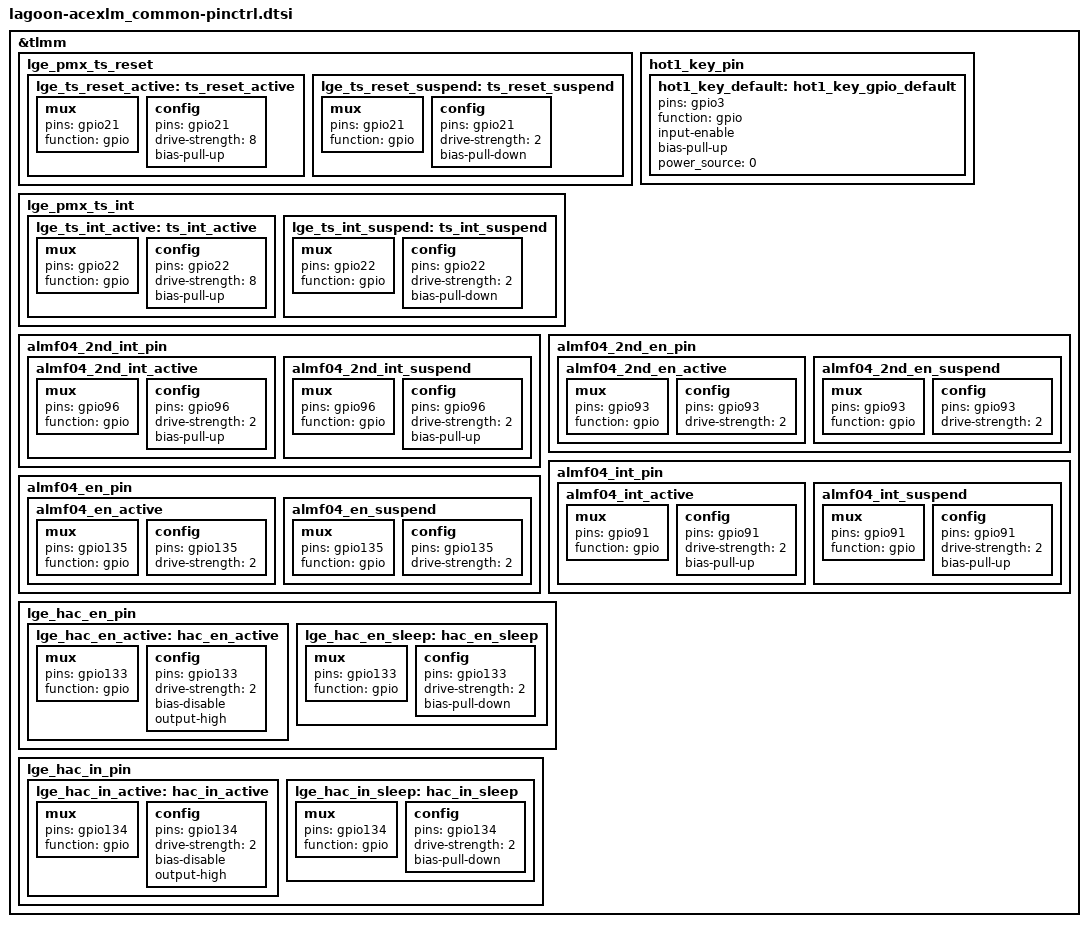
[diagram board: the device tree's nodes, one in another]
// SPDX-License-Identifier: GPL-2.0-only
/*
 * Copyright (c) 2018-2019, The Linux Foundation. All rights reserved.
 */

&tlmm {
	lge_pmx_ts_reset {
		lge_ts_reset_active: ts_reset_active {
			mux {
				pins = "gpio21";
				function = "gpio";
			};
			config {
				pins = "gpio21";
				drive-strength = <8>;
				bias-pull-up;
			};
		};

		lge_ts_reset_suspend: ts_reset_suspend {
			mux {
				pins = "gpio21";
				function = "gpio";
			};
			config {
				pins = "gpio21";
				drive-strength = <2>;
				bias-pull-down;
			};
		};
	};

	lge_pmx_ts_int {
		lge_ts_int_active: ts_int_active {
			mux {
				pins = "gpio22";
				function = "gpio";
			};
			config {
				pins = "gpio22";
				drive-strength = <8>;
				bias-pull-up;
			};
		};

		lge_ts_int_suspend: ts_int_suspend {
			mux {
				pins = "gpio22";
				function = "gpio";
			};
			config {
				pins = "gpio22";
				drive-strength = <2>;
				bias-pull-down;
			};
		};
	};

        hot1_key_pin {
                hot1_key_default: hot1_key_gpio_default {
                        pins = "gpio3";
                        function = "gpio";
                        input-enable;
                        bias-pull-up;
                        power_source = <0>;
                };
        };

	almf04_2nd_int_pin {
		almf04_2nd_int_active: almf04_2nd_int_active {
		       mux {
			   pins = "gpio96";
			   function = "gpio";
		       };
		       config {
			   pins = "gpio96";
			   drive-strength = <2>;   /* 2 MA */
			   bias-pull-up;           /* PULL UP*/
		       };
		   };

		almf04_2nd_int_suspend: almf04_2nd_int_suspend {
			mux {
			    pins = "gpio96";
			    function = "gpio";
			};
			config {
			    pins = "gpio96";
			    drive-strength = <2>;   /* 2 MA */
			    bias-pull-up;           /* PULL UP */
			};
		    };
	};
        almf04_2nd_en_pin {
                almf04_2nd_en_active: almf04_2nd_en_active {
                    mux {
                        pins = "gpio93";
                        function = "gpio";
                    };
                    config {
                        pins = "gpio93";
                        drive-strength = <2>;   /* 2 MA */
                    };
                };
                almf04_2nd_en_suspend: almf04_2nd_en_suspend {
                    mux {
                        pins = "gpio93";
                        function = "gpio";
                    };
                    config {
                        pins = "gpio93";
                        drive-strength = <2>;   /* 2 MA */
                    };
                };
        };

	almf04_int_pin {
		almf04_int_active: almf04_int_active {
		       mux {
			   pins = "gpio91";
			   function = "gpio";
		       };
		       config {
			   pins = "gpio91";
			   drive-strength = <2>;   /* 2 MA */
			   bias-pull-up;           /* PULL UP*/
		       };
		   };

		almf04_int_suspend: almf04_int_suspend {
			mux {
			    pins = "gpio91";
			    function = "gpio";
			};
			config {
			    pins = "gpio91";
			    drive-strength = <2>;   /* 2 MA */
			    bias-pull-up;           /* PULL UP */
			};
		    };
	};
        almf04_en_pin {
                almf04_en_active: almf04_en_active {
                    mux {
                        pins = "gpio135";
                        function = "gpio";
                    };
                    config {
                        pins = "gpio135";
                        drive-strength = <2>;   /* 2 MA */
                    };
                };
                almf04_en_suspend: almf04_en_suspend {
                    mux {
                        pins = "gpio135";
                        function = "gpio";
                    };
                    config {
                        pins = "gpio135";
                        drive-strength = <2>;   /* 2 MA */
                    };
                };
        };
	lge_hac_en_pin {
		lge_hac_en_active: hac_en_active {
			mux {
				pins = "gpio133";
				function = "gpio";
			};
			config {
				pins = "gpio133";
				drive-strength = <2>;  /* 2MA */
				bias-disable;
				output-high;
			};
		};
		lge_hac_en_sleep: hac_en_sleep {
			mux {
				pins = "gpio133";
				function = "gpio";
			};
			config {
				pins = "gpio133";
				drive-strength = <2>;  /* 2MA */
				bias-pull-down;
			};
		};
	};
	lge_hac_in_pin {
		lge_hac_in_active: hac_in_active {
			mux {
				pins = "gpio134";
				function = "gpio";
			};
			config {
				pins = "gpio134";
				drive-strength = <2>;  /* 2MA */
				bias-disable;
				output-high;
			};
		};
		lge_hac_in_sleep: hac_in_sleep {
			mux {
				pins = "gpio134";
				function = "gpio";
			};
			config {
				pins = "gpio134";
				drive-strength = <2>;  /* 2MA */
				bias-pull-down;
			};
		};
	};
};
